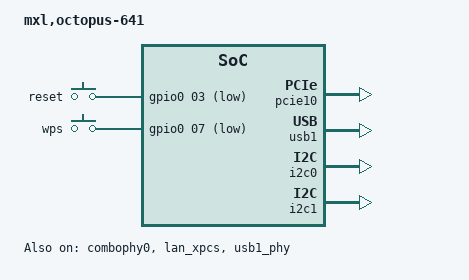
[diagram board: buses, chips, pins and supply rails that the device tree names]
// SPDX-License-Identifier: GPL-2.0
/*
 * Copyright (C) 2023-2024 MaxLinear, Inc.
 */
#include <dt-bindings/input/input.h>
#include "octopus_641.dtsi"

/******************************************************************************
** Board configuration: Enable buttons on the board.
******************************************************************************/
/ {
	gpio-keys-polled {
		compatible = "gpio-keys-polled";
		#address-cells = <1>;
		#size-cells = <0>;
		poll-interval = <100>;

		reset {
			label = "reset";
			gpios = <&gpio0 03 1>;
			linux,code = <KEY_RESTART>;
		};
		wps {
			label = "wps";
			gpios = <&gpio0 07 1>;
			linux,code = <KEY_WPS_BUTTON>;
		};
	};
};

/ {
	model = "mxl,octopus-641";

	chosen {
		/* ramfs */
		bootargs = "earlycon console=ttyLTQ0,115200n8r root=/dev/ram init=/init maxcpus=2 initcall_debug=0 clk_ignore_unused loglevel=8";
		stdout-path = "serial0";
	};
};


/* combo PHY setting */
/* combo phy 0 */
&combophy0 { /* PCIe10/11, HSIOL_XPCS0/1, SATA10/11 */ 
	status = "okay";
};

&p34x {
	/delete-property/ interrupt-parent;
	/delete-property/ interrupts;
	reset-gpios = <&gpio2 11 GPIO_ACTIVE_LOW>; /* GPIO 75 */
	interrupt-parent = <&gpio2>;
	pinctrl-names = "default";
	pinctrl-0 = <&pinctrl_mdint_gpio>;
	interrupts = <13 8>;
};

/* Enable P34x */
&lan_xpcs {
	status = "okay";
};

/* PCIe */
&pcie10 {
	status = "okay";
};

&usb1_phy {
	status = "okay";
	vbus-supply = <&usb_vbus>;
};

/* Add overcurrent interrupt support for USB */
/* Note: IO-APIC 46 is used for USB0 overcurrent detection (not available on octopus_641)
 *       IO-APIC 47 is used for USB0 host controller interrupt (not available on octopus_641)
 *       IO-APIC 48 is used for USB1 overcurrent detection
 *       IO-APIC 49 is used for USB1 host controller interrupt
 * Note: USB0 is not available on octopus_641 platform (deleted in octopus_641.dtsi)
 * Note: Overcurrent interrupt must be configured in dwc3@e6e00000 node, not in usb1 parent node,
 *       because DWC3 driver creates xHCI platform device from dwc3@e6e00000 resources
 */
&usb1 {
	status = "okay";
	dwc3@e6e00000 {
		interrupt-names = "host", "overcurrent";
		interrupt-parent = <&ioapic1>;
		interrupts = <49 1>, <48 1>; /* host interrupt, overcurrent interrupt */
	};
};

&i2c0 { /* used by PMIC */
	status = "okay";
};

&i2c1 { /* used by USB type-C */
	status = "okay";
};

&gphy0 {
	mxl,usxgmii-reach = <0>; /* 0(short), 1(medium), 2(long) */
};

&gphy1 {
	mxl,usxgmii-reach = <0>; /* 0(short), 1(medium), 2(long) */
};

&gphy2 {
	mxl,usxgmii-reach = <0>; /* 0(short), 1(medium), 2(long) */
};

&gphy3 {
	mxl,usxgmii-reach = <0>; /* 0(short), 1(medium), 2(long) */
};
